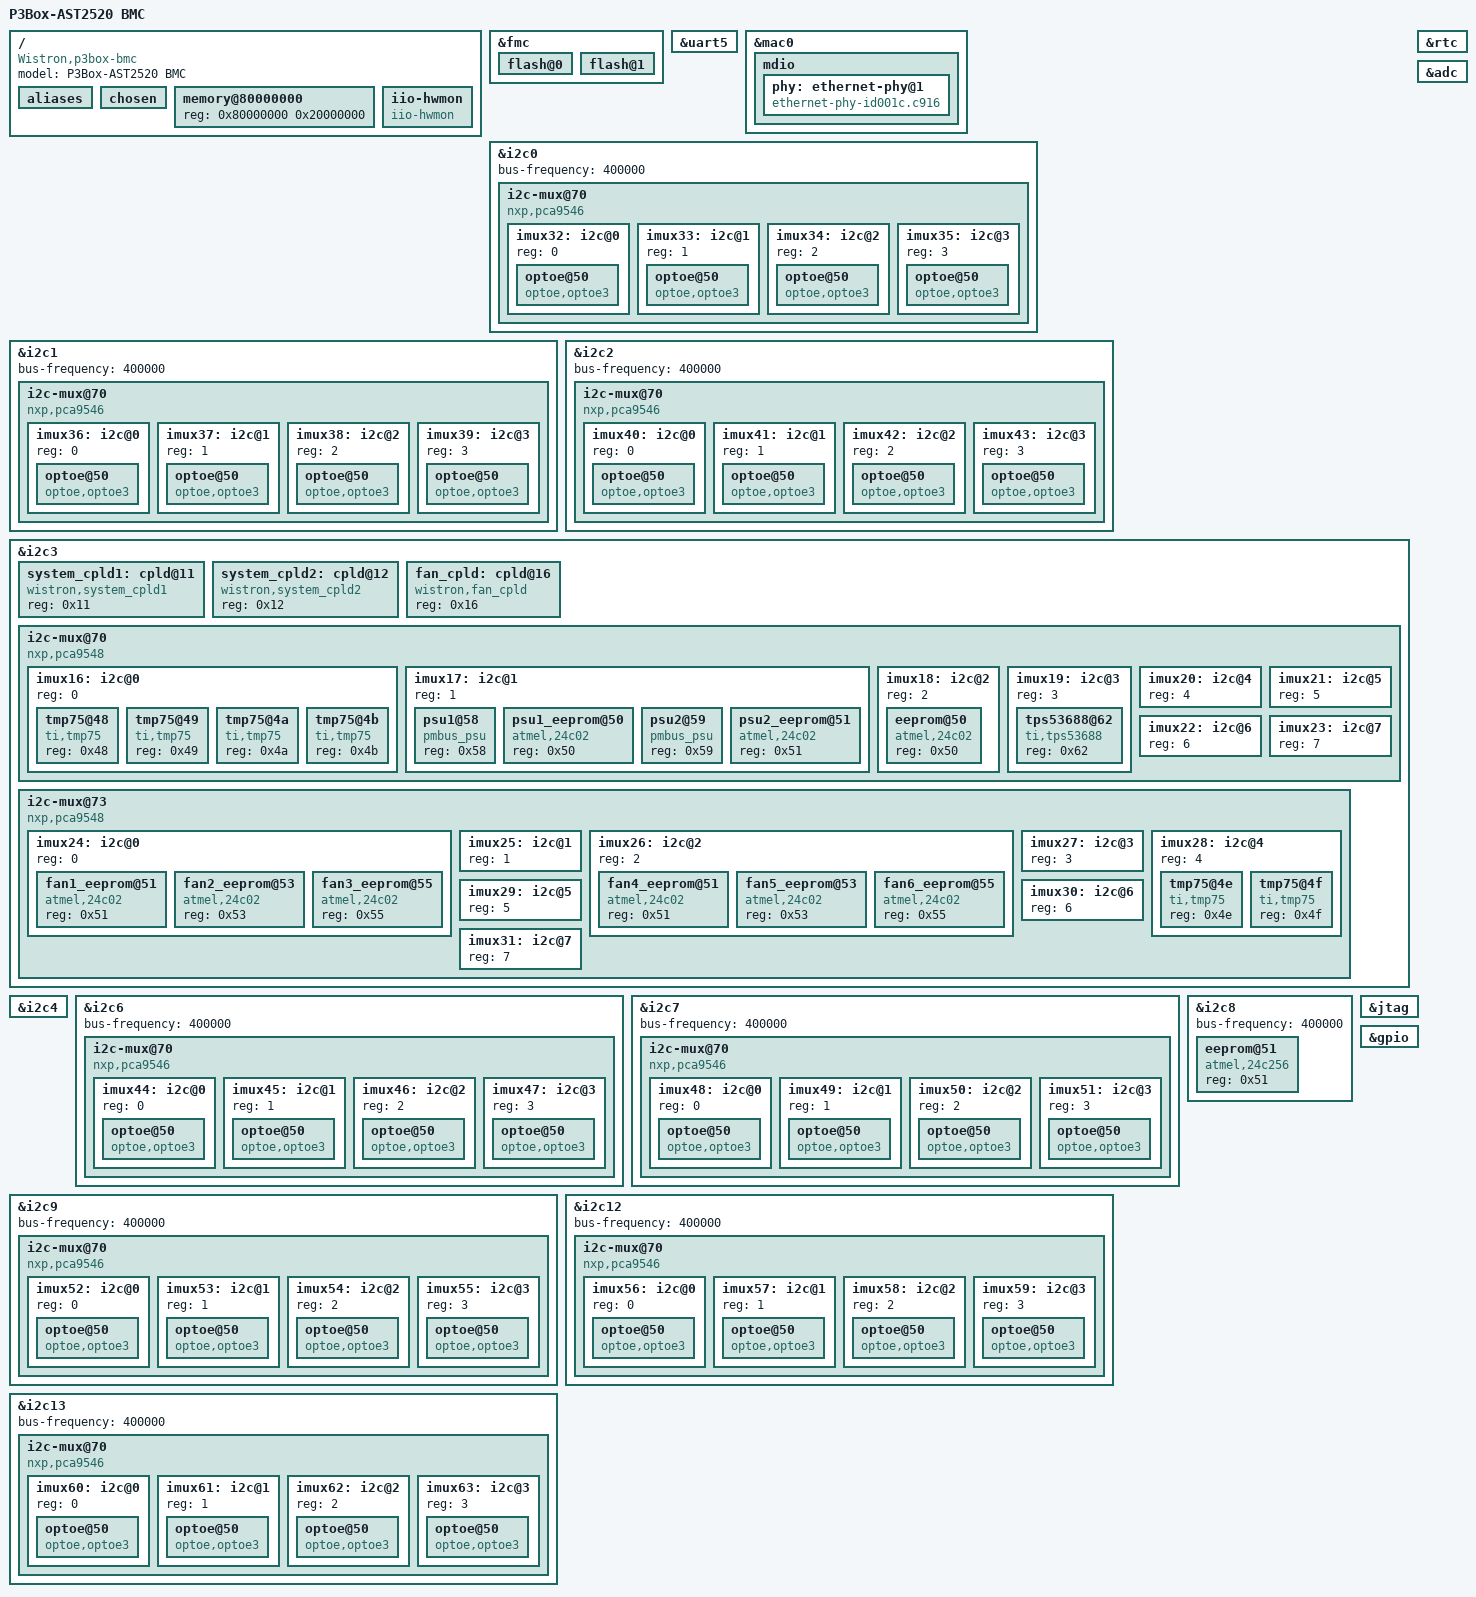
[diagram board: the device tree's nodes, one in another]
// SPDX-License-Identifier: GPL-2.0+
/dts-v1/;

#include "aspeed-g5.dtsi"
#include <dt-bindings/gpio/aspeed-gpio.h>
#include <dt-bindings/i2c/i2c.h>

/ {
	model = "P3Box-AST2520 BMC";
	compatible = "Wistron,p3box-bmc", "aspeed,ast2500";

	aliases {
		serial4 = &uart5;

		i2c16 = &imux16;
		i2c17 = &imux17;
		i2c18 = &imux18;
		i2c19 = &imux19;
		i2c20 = &imux20;
		i2c21 = &imux21;
		i2c22 = &imux22;
		i2c23 = &imux23;
		i2c24 = &imux24;
		i2c25 = &imux25;
		i2c26 = &imux26;
		i2c27 = &imux27;
		i2c28 = &imux28;
		i2c29 = &imux29;
		i2c30 = &imux30;
		i2c31 = &imux31;
		i2c32 = &imux32;
		i2c33 = &imux33;
		i2c34 = &imux34;
		i2c35 = &imux35;
		i2c36 = &imux36;
		i2c37 = &imux37;
		i2c38 = &imux38;
		i2c39 = &imux39;
		i2c40 = &imux40;
		i2c41 = &imux41;
		i2c42 = &imux42;
		i2c43 = &imux43;
		i2c44 = &imux44;
		i2c45 = &imux45;
		i2c46 = &imux46;
		i2c47 = &imux47;
		i2c48 = &imux48;
		i2c49 = &imux49;
		i2c50 = &imux50;
		i2c51 = &imux51;
		i2c52 = &imux52;
		i2c53 = &imux53;
		i2c54 = &imux54;
		i2c55 = &imux55;
		i2c56 = &imux56;
		i2c57 = &imux57;
		i2c58 = &imux58;
		i2c59 = &imux59;
		i2c60 = &imux60;
		i2c61 = &imux61;
		i2c62 = &imux62;
		i2c63 = &imux63;

		spi0 = &fmc;
	};

	chosen {
		stdout-path = &uart5;
		bootargs = "console=ttyS4,115200 root=/dev/ram rw mem.devmem=1";
	};

	memory@80000000 {
		reg = <0x80000000 0x20000000>;
	};

	iio-hwmon {
		compatible = "iio-hwmon";
		io-channels = <&adc 0>, <&adc 1>, <&adc 2>, <&adc 3>, <&adc 4>, <&adc 5>,
		              <&adc 6>, <&adc 8>, <&adc 9>;
	};
};

&fmc {
	status = "okay";
	flash@0 {
		status = "okay";
		m25p,fast-read;
		label = "bmc";
		spi-max-frequency = <50000000>;
#include "openbmc-flash-layout-128.dtsi"
	};

	flash@1 {
		status = "okay";
		m25p,fast-read;
		label = "alt-bmc";
		spi-max-frequency = <50000000>;
#include "openbmc-flash-layout-128-alt.dtsi"
	};
};

&uart5 {
	status = "okay";
};

&mac0 {
	status = "okay";
	pinctrl-names = "default";
	pinctrl-0 = <&pinctrl_rgmii1_default &pinctrl_mdio1_default>;
	phy-mode = "rgmii";
	phy-handle = <&phy>;

	mdio {
		#address-cells = <1>;
		#size-cells = <0>;

		phy: ethernet-phy@1 {
			/* RTL8211F */
			compatible = "ethernet-phy-id001c.c916";
			reg = <1>;

			realtek,reg-init = <0xd04 0x10 0x0 0x17b>;
		};
	};
};

&i2c0 {
	status = "okay";
	bus-frequency = <400000>;

	i2c-mux@70 {
		compatible = "nxp,pca9546";
		#address-cells = <1>;
		#size-cells = <0>;
		i2c-mux-idle-disconnect;
		reg = <0x70>;

		imux32: i2c@0 {
			#address-cells = <1>;
			#size-cells = <0>;
			reg = <0>;

			optoe@50 {
				compatible = "optoe,optoe3";
				reg = <0x50>;
				port_name = "Port1";
			};
		};

		imux33: i2c@1 {
			#address-cells = <1>;
			#size-cells = <0>;
			reg = <1>;

			optoe@50 {
				compatible = "optoe,optoe3";
				reg = <0x50>;
				port_name = "Port2";
			};
		};

		imux34: i2c@2 {
			#address-cells = <1>;
			#size-cells = <0>;
			reg = <2>;

			optoe@50 {
				compatible = "optoe,optoe3";
				reg = <0x50>;
				port_name = "Port3";
			};
		};

		imux35: i2c@3 {
			#address-cells = <1>;
			#size-cells = <0>;
			reg = <3>;

			optoe@50 {
				compatible = "optoe,optoe3";
				reg = <0x50>;
				port_name = "Port4";
			};
		};
	};
};

&i2c1 {
	status = "okay";
	bus-frequency = <400000>;

	i2c-mux@70 {
		compatible = "nxp,pca9546";
		#address-cells = <1>;
		#size-cells = <0>;
		i2c-mux-idle-disconnect;
		reg = <0x70>;

		imux36: i2c@0 {
			#address-cells = <1>;
			#size-cells = <0>;
			reg = <0>;

			optoe@50 {
				compatible = "optoe,optoe3";
				reg = <0x50>;
				port_name = "Port5";
			};
		};

		imux37: i2c@1 {
			#address-cells = <1>;
			#size-cells = <0>;
			reg = <1>;

			optoe@50 {
				compatible = "optoe,optoe3";
				reg = <0x50>;
				port_name = "Port6";
			};
		};

		imux38: i2c@2 {
			#address-cells = <1>;
			#size-cells = <0>;
			reg = <2>;

			optoe@50 {
				compatible = "optoe,optoe3";
				reg = <0x50>;
				port_name = "Port7";
			};
		};

		imux39: i2c@3 {
			#address-cells = <1>;
			#size-cells = <0>;
			reg = <3>;

			optoe@50 {
				compatible = "optoe,optoe3";
				reg = <0x50>;
				port_name = "Port8";
			};
		};
	};
};

&i2c2 {
	status = "okay";
	bus-frequency = <400000>;

	i2c-mux@70 {
		compatible = "nxp,pca9546";
		#address-cells = <1>;
		#size-cells = <0>;
		i2c-mux-idle-disconnect;
		reg = <0x70>;

		imux40: i2c@0 {
			#address-cells = <1>;
			#size-cells = <0>;
			reg = <0>;

			optoe@50 {
				compatible = "optoe,optoe3";
				reg = <0x50>;
				port_name = "Port9";
			};
		};

		imux41: i2c@1 {
			#address-cells = <1>;
			#size-cells = <0>;
			reg = <1>;

			optoe@50 {
				compatible = "optoe,optoe3";
				reg = <0x50>;
				port_name = "Port10";
			};
		};

		imux42: i2c@2 {
			#address-cells = <1>;
			#size-cells = <0>;
			reg = <2>;

			optoe@50 {
				compatible = "optoe,optoe3";
				reg = <0x50>;
				port_name = "Port11";
			};
		};

		imux43: i2c@3 {
			#address-cells = <1>;
			#size-cells = <0>;
			reg = <3>;

			optoe@50 {
				compatible = "optoe,optoe3";
				reg = <0x50>;
				port_name = "Port12";
			};
		};
	};
};

&i2c3 {
	status = "okay";

	system_cpld1: cpld@11 {
		compatible = "wistron,system_cpld1";
		reg = <0x11>;
	};

	system_cpld2: cpld@12 {
		compatible = "wistron,system_cpld2";
		reg = <0x12>;
	};

	fan_cpld: cpld@16 {
		compatible = "wistron,fan_cpld";
		reg = <0x16>;
	};

	i2c-mux@70 {
		compatible = "nxp,pca9548";
		#address-cells = <1>;
		#size-cells = <0>;
		i2c-mux-idle-disconnect;
		reg = <0x70>;

		imux16: i2c@0 {
			#address-cells = <1>;
			#size-cells = <0>;
			reg = <0>;

			/* MB Temperature1 */
			tmp75@48 {
				compatible = "ti,tmp75";
				reg = <0x48>;
			};

			/* MB Temperature2 */
			tmp75@49 {
				compatible = "ti,tmp75";
				reg = <0x49>;
			};

			/* MB Temperature3 */
			tmp75@4a {
				compatible = "ti,tmp75";
				reg = <0x4a>;
			};

			/* MB Temperature4 */
			tmp75@4b {
				compatible = "ti,tmp75";
				reg = <0x4b>;
			};
		};

		imux17: i2c@1 {
			#address-cells = <1>;
			#size-cells = <0>;
			reg = <1>;

			/* PSU1 MCU */
			psu1@58 {
				compatible = "pmbus_psu";
				reg = <0x58>;
			};

			/* PSU1 EEPROM */
			psu1_eeprom@50 {
				compatible = "atmel,24c02";
				reg = <0x50>;
			};

			/* PSU2 MCU */
			psu2@59 {
				compatible = "pmbus_psu";
				reg = <0x59>;
			};

			/* PSU2 EEPROM */
			psu2_eeprom@51 {
				compatible = "atmel,24c02";
				reg = <0x51>;
			};
		};

		imux18: i2c@2 {
			#address-cells = <1>;
			#size-cells = <0>;
			reg = <2>;

			/* MB EEPROM */
			eeprom@50 {
				compatible = "atmel,24c02";
				reg = <0x50>;
			};
		};

		imux19: i2c@3 {
			#address-cells = <1>;
			#size-cells = <0>;
			reg = <3>;

			tps53688@62 {
				compatible = "ti,tps53688";
				reg = <0x62>;
			};
		};

		imux20: i2c@4 {
			#address-cells = <1>;
			#size-cells = <0>;
			reg = <4>;
		};

		imux21: i2c@5 {
			#address-cells = <1>;
			#size-cells = <0>;
			reg = <5>;
		};

		imux22: i2c@6 {
			#address-cells = <1>;
			#size-cells = <0>;
			reg = <6>;
		};

		imux23: i2c@7 {
			#address-cells = <1>;
			#size-cells = <0>;
			reg = <7>;
		};
	};

	i2c-mux@73 {
		compatible = "nxp,pca9548";
		#address-cells = <1>;
		#size-cells = <0>;
		i2c-mux-idle-disconnect;
		reg = <0x73>;

		imux24: i2c@0 {
			#address-cells = <1>;
			#size-cells = <0>;
			reg = <0>;

			/* FAN1 EEPROM */
			fan1_eeprom@51 {
				compatible = "atmel,24c02";
				reg = <0x51>;
			};

			/* FAN2 EEPROM */
			fan2_eeprom@53 {
				compatible = "atmel,24c02";
				reg = <0x53>;
			};

			/* FAN3 EEPROM */
			fan3_eeprom@55 {
				compatible = "atmel,24c02";
				reg = <0x55>;
			};
		};

		imux25: i2c@1 {
			#address-cells = <1>;
			#size-cells = <0>;
			reg = <1>;
		};

		imux26: i2c@2 {
			#address-cells = <1>;
			#size-cells = <0>;
			reg = <2>;

			/* FAN4 EEPROM */
			fan4_eeprom@51 {
				compatible = "atmel,24c02";
				reg = <0x51>;
			};

			/* FAN5 EEPROM */
			fan5_eeprom@53 {
				compatible = "atmel,24c02";
				reg = <0x53>;
			};

			/* FAN6 EEPROM */
			fan6_eeprom@55 {
				compatible = "atmel,24c02";
				reg = <0x55>;
			};
		};

		imux27: i2c@3 {
			#address-cells = <1>;
			#size-cells = <0>;
			reg = <3>;
		};

		imux28: i2c@4 {
			#address-cells = <1>;
			#size-cells = <0>;
			reg = <4>;

			/* FAN Temperature1 */
			tmp75@4e {
				compatible = "ti,tmp75";
				reg = <0x4e>;
			};

			/* FAN Temperature2 */
			tmp75@4f {
				compatible = "ti,tmp75";
				reg = <0x4f>;
			};
		};

		imux29: i2c@5 {
			#address-cells = <1>;
			#size-cells = <0>;
			reg = <5>;
		};

		imux30: i2c@6 {
			#address-cells = <1>;
			#size-cells = <0>;
			reg = <6>;
		};

		imux31: i2c@7 {
			#address-cells = <1>;
			#size-cells = <0>;
			reg = <7>;
		};
	};
};

/* For CPLD remote update */
&i2c4 {
	status = "okay";
};

&i2c6 {
	status = "okay";
	bus-frequency = <400000>;

	i2c-mux@70 {
		compatible = "nxp,pca9546";
		#address-cells = <1>;
		#size-cells = <0>;
		i2c-mux-idle-disconnect;
		reg = <0x70>;

		imux44: i2c@0 {
			#address-cells = <1>;
			#size-cells = <0>;
			reg = <0>;

			optoe@50 {
				compatible = "optoe,optoe3";
				reg = <0x50>;
				port_name = "Port13";
			};
		};

		imux45: i2c@1 {
			#address-cells = <1>;
			#size-cells = <0>;
			reg = <1>;

			optoe@50 {
				compatible = "optoe,optoe3";
				reg = <0x50>;
				port_name = "Port14";
			};
		};

		imux46: i2c@2 {
			#address-cells = <1>;
			#size-cells = <0>;
			reg = <2>;

			optoe@50 {
				compatible = "optoe,optoe3";
				reg = <0x50>;
				port_name = "Port15";
			};
		};

		imux47: i2c@3 {
			#address-cells = <1>;
			#size-cells = <0>;
			reg = <3>;

			optoe@50 {
				compatible = "optoe,optoe3";
				reg = <0x50>;
				port_name = "Port16";
			};
		};
	};
};

&i2c7 {
	status = "okay";
	bus-frequency = <400000>;

	i2c-mux@70 {
		compatible = "nxp,pca9546";
		#address-cells = <1>;
		#size-cells = <0>;
		i2c-mux-idle-disconnect;
		reg = <0x70>;

		imux48: i2c@0 {
			#address-cells = <1>;
			#size-cells = <0>;
			reg = <0>;

			optoe@50 {
				compatible = "optoe,optoe3";
				reg = <0x50>;
				port_name = "Port17";
			};
		};

		imux49: i2c@1 {
			#address-cells = <1>;
			#size-cells = <0>;
			reg = <1>;

			optoe@50 {
				compatible = "optoe,optoe3";
				reg = <0x50>;
				port_name = "Port18";
			};
		};

		imux50: i2c@2 {
			#address-cells = <1>;
			#size-cells = <0>;
			reg = <2>;

			optoe@50 {
				compatible = "optoe,optoe3";
				reg = <0x50>;
				port_name = "Port19";
			};
		};

		imux51: i2c@3 {
			#address-cells = <1>;
			#size-cells = <0>;
			reg = <3>;

			optoe@50 {
				compatible = "optoe,optoe3";
				reg = <0x50>;
				port_name = "Port20";
			};
		};
	};
};

/* BMC FRU EEPROM */
&i2c8 {
	status = "okay";
	bus-frequency = <400000>;

	eeprom@51 {
		compatible = "atmel,24c256";
		reg = <0x51>;
	};
};

&i2c9 {
	status = "okay";
	bus-frequency = <400000>;

	i2c-mux@70 {
		compatible = "nxp,pca9546";
		#address-cells = <1>;
		#size-cells = <0>;
		i2c-mux-idle-disconnect;
		reg = <0x70>;

		imux52: i2c@0 {
			#address-cells = <1>;
			#size-cells = <0>;
			reg = <0>;

			optoe@50 {
				compatible = "optoe,optoe3";
				reg = <0x50>;
				port_name = "Port21";
			};
		};

		imux53: i2c@1 {
			#address-cells = <1>;
			#size-cells = <0>;
			reg = <1>;

			optoe@50 {
				compatible = "optoe,optoe3";
				reg = <0x50>;
				port_name = "Port22";
			};
		};

		imux54: i2c@2 {
			#address-cells = <1>;
			#size-cells = <0>;
			reg = <2>;

			optoe@50 {
				compatible = "optoe,optoe3";
				reg = <0x50>;
				port_name = "Port23";
			};
		};

		imux55: i2c@3 {
			#address-cells = <1>;
			#size-cells = <0>;
			reg = <3>;

			optoe@50 {
				compatible = "optoe,optoe3";
				reg = <0x50>;
				port_name = "Port24";
			};
		};
	};
};

&i2c12 {
	status = "okay";
	bus-frequency = <400000>;

	i2c-mux@70 {
		compatible = "nxp,pca9546";
		#address-cells = <1>;
		#size-cells = <0>;
		i2c-mux-idle-disconnect;
		reg = <0x70>;

		imux56: i2c@0 {
			#address-cells = <1>;
			#size-cells = <0>;
			reg = <0>;

			optoe@50 {
				compatible = "optoe,optoe3";
				reg = <0x50>;
				port_name = "Port25";
			};
		};

		imux57: i2c@1 {
			#address-cells = <1>;
			#size-cells = <0>;
			reg = <1>;

			optoe@50 {
				compatible = "optoe,optoe3";
				reg = <0x50>;
				port_name = "Port26";
			};
		};

		imux58: i2c@2 {
			#address-cells = <1>;
			#size-cells = <0>;
			reg = <2>;

			optoe@50 {
				compatible = "optoe,optoe3";
				reg = <0x50>;
				port_name = "Port27";
			};
		};

		imux59: i2c@3 {
			#address-cells = <1>;
			#size-cells = <0>;
			reg = <3>;

			optoe@50 {
				compatible = "optoe,optoe3";
				reg = <0x50>;
				port_name = "Port28";
			};
		};
	};
};

&i2c13 {
	status = "okay";
	bus-frequency = <400000>;

	i2c-mux@70 {
		compatible = "nxp,pca9546";
		#address-cells = <1>;
		#size-cells = <0>;
		i2c-mux-idle-disconnect;
		reg = <0x70>;

		imux60: i2c@0 {
			#address-cells = <1>;
			#size-cells = <0>;
			reg = <0>;

			optoe@50 {
				compatible = "optoe,optoe3";
				reg = <0x50>;
				port_name = "Port29";
			};
		};

		imux61: i2c@1 {
			#address-cells = <1>;
			#size-cells = <0>;
			reg = <1>;

			optoe@50 {
				compatible = "optoe,optoe3";
				reg = <0x50>;
				port_name = "Port30";
			};
		};

		imux62: i2c@2 {
			#address-cells = <1>;
			#size-cells = <0>;
			reg = <2>;

			optoe@50 {
				compatible = "optoe,optoe3";
				reg = <0x50>;
				port_name = "Port31";
			};
		};

		imux63: i2c@3 {
			#address-cells = <1>;
			#size-cells = <0>;
			reg = <3>;

			optoe@50 {
				compatible = "optoe,optoe3";
				reg = <0x50>;
				port_name = "Port32";
			};
		};
	};
};

&rtc {
	status = "okay";
};

&adc {
	status = "okay";
	pinctrl-names = "default";
	pinctrl-0 = <&pinctrl_adc0_default
	             &pinctrl_adc1_default
	             &pinctrl_adc2_default
	             &pinctrl_adc3_default
	             &pinctrl_adc4_default
	             &pinctrl_adc5_default
	             &pinctrl_adc6_default
	             &pinctrl_adc8_default
	             &pinctrl_adc9_default>;
};

&jtag {
	status = "okay";
};

&gpio {
	status = "okay";

	gpio-line-names =
	/*A0-A7*/   "","","","","","","","",
	/*B0-B7*/   "PostComplete","PowerButton","ResetButton","","","","","",
	/*C0-C7*/   "","","","","","","","",
	/*D0-D7*/   "FM_PWR_BTN_BMC_N","FM_BMC_RST_BTN_N","","","","","","",
	/*E0-E7*/   "","","","","","","","",
	/*F0-F7*/   "","","","","","","","",
	/*G0-G7*/   "","","","","","","","",
	/*H0-H7*/   "","","","","","","","",
	/*I0-I7*/   "","","","","","","","",
	/*J0-J7*/   "","","","","","","","",
	/*K0-K7*/   "","","","","","","","",
	/*L0-L7*/   "","","","","","","","",
	/*M0-M7*/   "PWRGD_SYSTEM","","","","","","","",
	/*N0-N7*/   "","","","","","","","",
	/*O0-O7*/   "","","","","","","","",
	/*P0-P7*/   "","","","","","","","",
	/*Q0-Q7*/   "","","","","","","","",
	/*R0-R7*/   "","","","","","","","",
	/*S0-S7*/   "","","","","","","","",
	/*T0-T7*/   "","","","","","","","",
	/*U0-U7*/   "","","","","","","","",
	/*V0-V7*/   "","","","","","","","",
	/*W0-W7*/   "","","","","","","","",
	/*X0-X7*/   "","","","","","","","",
	/*Y0-Y7*/   "","","","","","","","",
	/*Z0-Z7*/   "","","","","","","","",
	/*AA0-AA7*/ "","","","","","","","",
	/*AB0-AB7*/ "","","","","","","","",
	/*AC0-AC7*/ "","","","","","","","";
};
